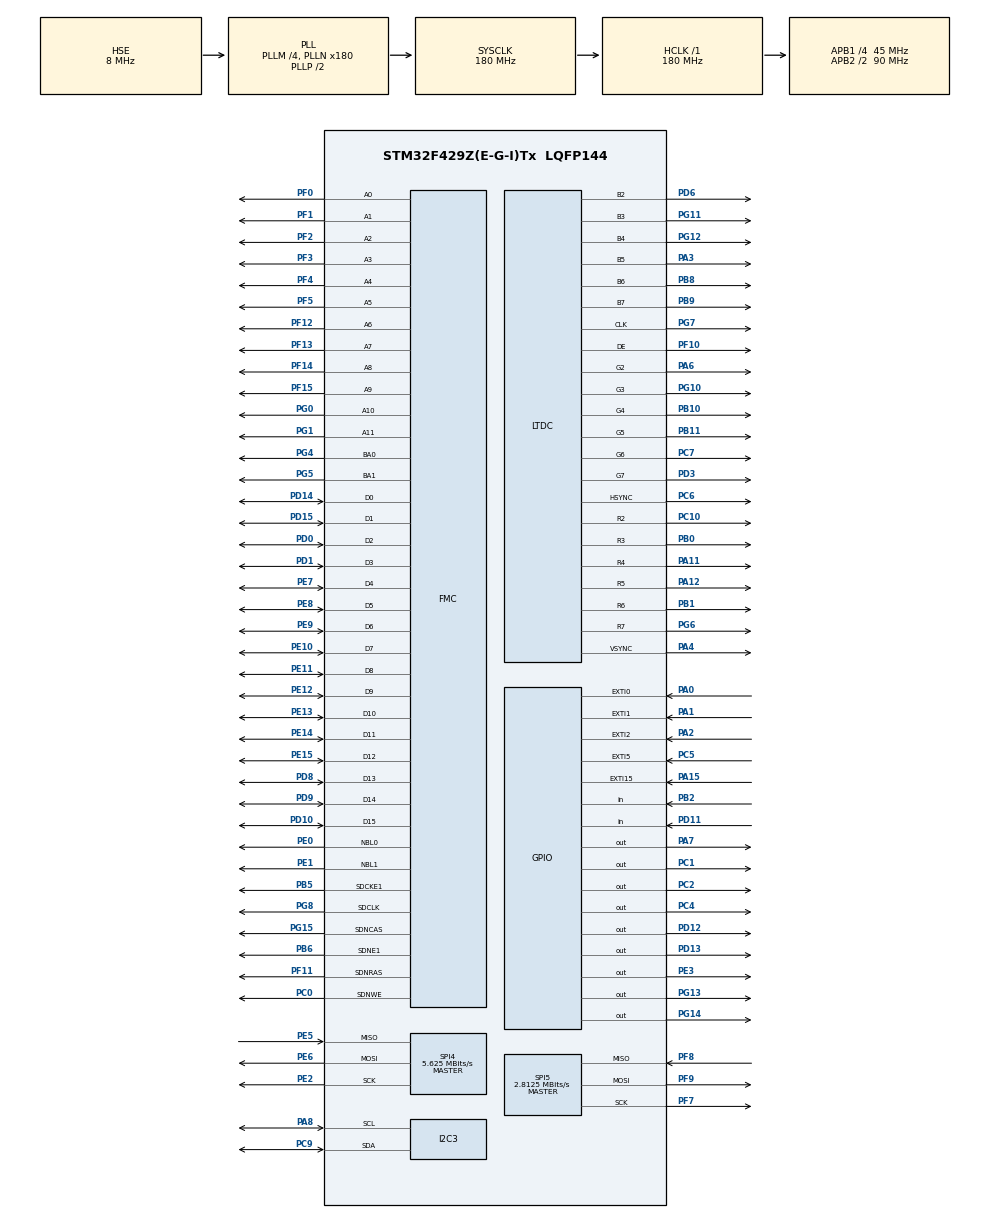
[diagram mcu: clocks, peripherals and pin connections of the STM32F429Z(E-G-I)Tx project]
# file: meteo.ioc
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DMA2D.InputColorModeForeground=DMA2D_INPUT_RGB888
DMA2D.Mode=DMA2D_M2M_PFC
FMC.CASLatency1=FMC_SDRAM_CAS_LATENCY_3
FMC.ExitSelfRefreshDelay1=7
FMC.LoadToActiveDelay1=2
FMC.RCDDelay1=2
FMC.RPDelay1=2
FMC.RPDelay2=2
FMC.ReadPipeDelay1=FMC_SDRAM_RPIPE_DELAY_1
FMC.ReadPipeDelay2=FMC_SDRAM_RPIPE_DELAY_1
FMC.RowCycleDelay1=7
FMC.RowCycleDelay2=7
FMC.SelfRefreshTime1=4
FMC.WriteRecoveryTime1=3
LTDC.ActiveH=320
LTDC.ActiveW=240
LTDC.Alpha0_L0=0
LTDC.Alpha_L0=255
LTDC.BlendingFactor1_L0=LTDC_BLENDING_FACTOR1_PAxCA
LTDC.BlendingFactor2_L0=LTDC_BLENDING_FACTOR2_PAxCA
LTDC.HBP=20
LTDC.HFP=10
LTDC.HSync=10
LTDC.ImageHeight_L0=320
LTDC.ImageWidth_L0=240
LTDC.Layers=0
LTDC.VFP=4
LTDC.VSync=2
LTDC.WindowX1_L0=240
LTDC.WindowY1_L0=320
Mcu.Family=STM32F4
Mcu.Name=STM32F429Z(E-G-I)Tx
Mcu.Package=LQFP144
NVIC.FMC_IRQn=true\:0\:0\:false\:false\:true
NVIC.PriorityGroup=NVIC_PRIORITYGROUP_0
PA0/WKUP.GPIO_ModeDefaultEXTI=GPIO_MODE_IT_RISING
PA0/WKUP.GPIO_PuPd=GPIO_NOPULL
PA0/WKUP.Signal=GPXTI0
PA1.GPIO_ModeDefaultEXTI=GPIO_MODE_IT_RISING
PA1.GPIO_PuPd=GPIO_NOPULL
PA1.Signal=GPXTI1
PA11.GPIO_Mode=GPIO_MODE_AF_PP
PA11.GPIO_PuPd=GPIO_NOPULL
PA11.GPIO_Speed=GPIO_SPEED_FREQ_HIGH
PA11.Mode=RGB666
PA11.Signal=LTDC_R4
PA12.GPIO_Mode=GPIO_MODE_AF_PP
PA12.GPIO_PuPd=GPIO_NOPULL
PA12.GPIO_Speed=GPIO_SPEED_FREQ_HIGH
PA12.Mode=RGB666
PA12.Signal=LTDC_R5
PA13.Mode=Trace_Asynchronous_SW
PA13.Signal=SYS_JTMS-SWDIO
PA14.Mode=Trace_Asynchronous_SW
PA14.Signal=SYS_JTCK-SWCLK
PA15.GPIO_ModeDefaultEXTI=GPIO_MODE_IT_RISING
PA15.GPIO_PuPd=GPIO_NOPULL
PA15.Signal=GPXTI15
PA2.GPIO_ModeDefaultEXTI=GPIO_MODE_IT_RISING
PA2.GPIO_PuPd=GPIO_NOPULL
PA2.Signal=GPXTI2
PA3.GPIO_Mode=GPIO_MODE_AF_PP
PA3.GPIO_PuPd=GPIO_NOPULL
PA3.GPIO_Speed=GPIO_SPEED_FREQ_HIGH
PA3.Mode=RGB666
PA3.Signal=LTDC_B5
PA4.GPIO_Mode=GPIO_MODE_AF_PP
PA4.GPIO_PuPd=GPIO_NOPULL
PA4.GPIO_Speed=GPIO_SPEED_FREQ_HIGH
PA4.Mode=RGB666
PA4.Signal=LTDC_VSYNC
PA6.GPIO_Mode=GPIO_MODE_AF_PP
PA6.GPIO_PuPd=GPIO_NOPULL
PA6.GPIO_Speed=GPIO_SPEED_FREQ_HIGH
PA6.Mode=RGB666
PA6.Signal=LTDC_G2
PA7.GPIO_Mode=GPIO_MODE_OUTPUT_PP
PA7.GPIO_ModeDefaultOutputPP=GPIO_MODE_OUTPUT_PP
PA7.GPIO_PuPd=GPIO_NOPULL
PA7.GPIO_Speed=GPIO_SPEED_FREQ_LOW
PA7.PinState=GPIO_PIN_RESET
PA7.Signal=GPIO_Output
PA8.GPIO_Mode=GPIO_MODE_AF_OD
PA8.GPIO_PuPd=GPIO_NOPULL
PA8.GPIO_PuPdOD=GPIO_PULLUP
PA8.GPIO_Speed=GPIO_SPEED_FREQ_VERY_HIGH
PA8.Mode=I2C
PA8.Signal=I2C3_SCL
PB0.GPIO_Mode=GPIO_MODE_AF_PP
PB0.GPIO_PuPd=GPIO_NOPULL
PB0.GPIO_Speed=GPIO_SPEED_FREQ_HIGH
PB0.Mode=RGB666
PB0.Signal=LTDC_R3
PB1.GPIO_Mode=GPIO_MODE_AF_PP
PB1.GPIO_PuPd=GPIO_NOPULL
PB1.GPIO_Speed=GPIO_SPEED_FREQ_HIGH
PB1.Mode=RGB666
PB1.Signal=LTDC_R6
PB10.GPIO_Mode=GPIO_MODE_AF_PP
PB10.GPIO_PuPd=GPIO_NOPULL
PB10.GPIO_Speed=GPIO_SPEED_FREQ_HIGH
PB10.Mode=RGB666
PB10.Signal=LTDC_G4
PB11.GPIO_Mode=GPIO_MODE_AF_PP
PB11.GPIO_PuPd=GPIO_NOPULL
PB11.GPIO_Speed=GPIO_SPEED_FREQ_HIGH
PB11.Mode=RGB666
PB11.Signal=LTDC_G5
PB12.GPIO_Mode=GPIO_MODE_AF_PP
PB12.GPIO_PuPd=GPIO_NOPULL
PB12.GPIO_Speed=GPIO_SPEED_FREQ_VERY_HIGH
PB12.Signal=USB_OTG_HS_ID
PB13.GPIO_Mode=GPIO_MODE_INPUT
PB13.GPIO_PuPd=GPIO_NOPULL
PB13.Signal=USB_OTG_HS_VBUS
PB14.GPIO_Mode=GPIO_MODE_AF_PP
PB14.GPIO_PuPd=GPIO_NOPULL
PB14.GPIO_Speed=GPIO_SPEED_FREQ_VERY_HIGH
PB14.Signal=USB_OTG_HS_DM
PB15.GPIO_Mode=GPIO_MODE_AF_PP
PB15.GPIO_PuPd=GPIO_NOPULL
PB15.GPIO_Speed=GPIO_SPEED_FREQ_VERY_HIGH
PB15.Signal=USB_OTG_HS_DP
PB2/BOOT1.GPIO_Mode=GPIO_MODE_INPUT
PB2/BOOT1.GPIO_PuPd=GPIO_NOPULL
PB2/BOOT1.Signal=GPIO_Input
PB3.Mode=Trace_Asynchronous_SW
PB3.Signal=SYS_JTDO-SWO
PB5.GPIO_Mode=GPIO_MODE_AF_PP
PB5.GPIO_PuPd=GPIO_NOPULL
PB5.GPIO_Speed=GPIO_SPEED_FREQ_VERY_HIGH
PB5.GPIO_Speed_High_Default=GPIO_SPEED_FREQ_VERY_HIGH
PB5.Mode=SdramChipSelect2_1
PB5.Signal=FMC_SDCKE1
PB6.GPIO_Mode=GPIO_MODE_AF_PP
PB6.GPIO_PuPd=GPIO_NOPULL
PB6.GPIO_Speed=GPIO_SPEED_FREQ_VERY_HIGH
PB6.GPIO_Speed_High_Default=GPIO_SPEED_FREQ_VERY_HIGH
PB6.Mode=SdramChipSelect2_1
PB6.Signal=FMC_SDNE1
PB8.GPIO_Mode=GPIO_MODE_AF_PP
PB8.GPIO_PuPd=GPIO_NOPULL
PB8.GPIO_Speed=GPIO_SPEED_FREQ_HIGH
PB8.Mode=RGB666
PB8.Signal=LTDC_B6
PB9.GPIO_Mode=GPIO_MODE_AF_PP
PB9.GPIO_PuPd=GPIO_NOPULL
PB9.GPIO_Speed=GPIO_SPEED_FREQ_HIGH
PB9.Mode=RGB666
PB9.Signal=LTDC_B7
PC0.GPIO_Mode=GPIO_MODE_AF_PP
PC0.GPIO_PuPd=GPIO_NOPULL
PC0.GPIO_Speed=GPIO_SPEED_FREQ_VERY_HIGH
PC0.GPIO_Speed_High_Default=GPIO_SPEED_FREQ_VERY_HIGH
PC0.Signal=FMC_SDNWE
PC1.GPIO_Mode=GPIO_MODE_OUTPUT_PP
PC1.GPIO_ModeDefaultOutputPP=GPIO_MODE_OUTPUT_PP
PC1.GPIO_PuPd=GPIO_NOPULL
PC1.GPIO_Speed=GPIO_SPEED_FREQ_LOW
PC1.PinState=GPIO_PIN_RESET
PC1.Signal=GPIO_Output
PC10.GPIO_Mode=GPIO_MODE_AF_PP
PC10.GPIO_PuPd=GPIO_NOPULL
PC10.GPIO_Speed=GPIO_SPEED_FREQ_HIGH
PC10.Mode=RGB666
PC10.Signal=LTDC_R2
PC14/OSC32_IN.Signal=RCC_OSC32_IN
PC15/OSC32_OUT.Signal=RCC_OSC32_OUT
PC2.GPIO_Mode=GPIO_MODE_OUTPUT_PP
PC2.GPIO_ModeDefaultOutputPP=GPIO_MODE_OUTPUT_PP
PC2.GPIO_PuPd=GPIO_NOPULL
PC2.GPIO_Speed=GPIO_SPEED_FREQ_LOW
PC2.PinState=GPIO_PIN_RESET
PC2.Signal=GPIO_Output
PC4.GPIO_Mode=GPIO_MODE_OUTPUT_PP
PC4.GPIO_ModeDefaultOutputPP=GPIO_MODE_OUTPUT_PP
PC4.GPIO_PuPd=GPIO_NOPULL
PC4.GPIO_Speed=GPIO_SPEED_FREQ_LOW
PC4.PinState=GPIO_PIN_RESET
PC4.Signal=GPIO_Output
PC5.GPIO_ModeDefaultEXTI=GPIO_MODE_IT_RISING
PC5.GPIO_PuPd=GPIO_NOPULL
PC5.Signal=GPXTI5
PC6.GPIO_Mode=GPIO_MODE_AF_PP
PC6.GPIO_PuPd=GPIO_NOPULL
PC6.GPIO_Speed=GPIO_SPEED_FREQ_HIGH
PC6.Mode=RGB666
PC6.Signal=LTDC_HSYNC
PC7.GPIO_Mode=GPIO_MODE_AF_PP
PC7.GPIO_PuPd=GPIO_NOPULL
PC7.GPIO_Speed=GPIO_SPEED_FREQ_HIGH
PC7.Mode=RGB666
PC7.Signal=LTDC_G6
PC9.GPIO_Mode=GPIO_MODE_AF_OD
PC9.GPIO_PuPd=GPIO_NOPULL
PC9.GPIO_PuPdOD=GPIO_PULLUP
PC9.GPIO_Speed=GPIO_SPEED_FREQ_VERY_HIGH
PC9.Mode=I2C
PC9.Signal=I2C3_SDA
PD0.GPIO_Mode=GPIO_MODE_AF_PP
PD0.GPIO_PuPd=GPIO_NOPULL
PD0.GPIO_Speed=GPIO_SPEED_FREQ_VERY_HIGH
PD0.GPIO_Speed_High_Default=GPIO_SPEED_FREQ_VERY_HIGH
PD0.Signal=FMC_D2_DA2
PD1.GPIO_Mode=GPIO_MODE_AF_PP
PD1.GPIO_PuPd=GPIO_NOPULL
PD1.GPIO_Speed=GPIO_SPEED_FREQ_VERY_HIGH
PD1.GPIO_Speed_High_Default=GPIO_SPEED_FREQ_VERY_HIGH
PD1.Signal=FMC_D3_DA3
PD10.GPIO_Mode=GPIO_MODE_AF_PP
PD10.GPIO_PuPd=GPIO_NOPULL
PD10.GPIO_Speed=GPIO_SPEED_FREQ_VERY_HIGH
PD10.GPIO_Speed_High_Default=GPIO_SPEED_FREQ_VERY_HIGH
PD10.Signal=FMC_D15_DA15
PD11.GPIO_Mode=GPIO_MODE_INPUT
PD11.GPIO_PuPd=GPIO_NOPULL
PD11.Signal=GPIO_Input
PD12.GPIO_Mode=GPIO_MODE_OUTPUT_PP
PD12.GPIO_ModeDefaultOutputPP=GPIO_MODE_OUTPUT_PP
PD12.GPIO_PuPd=GPIO_NOPULL
PD12.GPIO_Speed=GPIO_SPEED_FREQ_LOW
PD12.PinState=GPIO_PIN_RESET
PD12.Signal=GPIO_Output
PD13.GPIO_Mode=GPIO_MODE_OUTPUT_PP
PD13.GPIO_ModeDefaultOutputPP=GPIO_MODE_OUTPUT_PP
PD13.GPIO_PuPd=GPIO_NOPULL
PD13.GPIO_Speed=GPIO_SPEED_FREQ_LOW
PD13.PinState=GPIO_PIN_RESET
PD13.Signal=GPIO_Output
PD14.GPIO_Mode=GPIO_MODE_AF_PP
PD14.GPIO_PuPd=GPIO_NOPULL
PD14.GPIO_Speed=GPIO_SPEED_FREQ_VERY_HIGH
PD14.GPIO_Speed_High_Default=GPIO_SPEED_FREQ_VERY_HIGH
PD14.Signal=FMC_D0_DA0
PD15.GPIO_Mode=GPIO_MODE_AF_PP
PD15.GPIO_PuPd=GPIO_NOPULL
PD15.GPIO_Speed=GPIO_SPEED_FREQ_VERY_HIGH
PD15.GPIO_Speed_High_Default=GPIO_SPEED_FREQ_VERY_HIGH
PD15.Signal=FMC_D1_DA1
PD3.GPIO_Mode=GPIO_MODE_AF_PP
PD3.GPIO_PuPd=GPIO_NOPULL
PD3.GPIO_Speed=GPIO_SPEED_FREQ_HIGH
PD3.Mode=RGB666
PD3.Signal=LTDC_G7
PD6.GPIO_Mode=GPIO_MODE_AF_PP
PD6.GPIO_PuPd=GPIO_NOPULL
PD6.GPIO_Speed=GPIO_SPEED_FREQ_HIGH
PD6.Mode=RGB666
PD6.Signal=LTDC_B2
PD8.GPIO_Mode=GPIO_MODE_AF_PP
PD8.GPIO_PuPd=GPIO_NOPULL
PD8.GPIO_Speed=GPIO_SPEED_FREQ_VERY_HIGH
PD8.GPIO_Speed_High_Default=GPIO_SPEED_FREQ_VERY_HIGH
PD8.Signal=FMC_D13_DA13
PD9.GPIO_Mode=GPIO_MODE_AF_PP
PD9.GPIO_PuPd=GPIO_NOPULL
PD9.GPIO_Speed=GPIO_SPEED_FREQ_VERY_HIGH
PD9.GPIO_Speed_High_Default=GPIO_SPEED_FREQ_VERY_HIGH
PD9.Signal=FMC_D14_DA14
PE0.GPIO_Mode=GPIO_MODE_AF_PP
PE0.GPIO_PuPd=GPIO_NOPULL
PE0.GPIO_Speed=GPIO_SPEED_FREQ_VERY_HIGH
PE0.GPIO_Speed_High_Default=GPIO_SPEED_FREQ_VERY_HIGH
PE0.Signal=FMC_NBL0
PE1.GPIO_Mode=GPIO_MODE_AF_PP
PE1.GPIO_PuPd=GPIO_NOPULL
PE1.GPIO_Speed=GPIO_SPEED_FREQ_VERY_HIGH
PE1.GPIO_Speed_High_Default=GPIO_SPEED_FREQ_VERY_HIGH
PE1.Signal=FMC_NBL1
PE10.GPIO_Mode=GPIO_MODE_AF_PP
PE10.GPIO_PuPd=GPIO_NOPULL
PE10.GPIO_Speed=GPIO_SPEED_FREQ_VERY_HIGH
PE10.GPIO_Speed_High_Default=GPIO_SPEED_FREQ_VERY_HIGH
PE10.Signal=FMC_D7_DA7
PE11.GPIO_Mode=GPIO_MODE_AF_PP
PE11.GPIO_PuPd=GPIO_NOPULL
PE11.GPIO_Speed=GPIO_SPEED_FREQ_VERY_HIGH
PE11.GPIO_Speed_High_Default=GPIO_SPEED_FREQ_VERY_HIGH
PE11.Signal=FMC_D8_DA8
PE12.GPIO_Mode=GPIO_MODE_AF_PP
PE12.GPIO_PuPd=GPIO_NOPULL
PE12.GPIO_Speed=GPIO_SPEED_FREQ_VERY_HIGH
PE12.GPIO_Speed_High_Default=GPIO_SPEED_FREQ_VERY_HIGH
PE12.Signal=FMC_D9_DA9
PE13.GPIO_Mode=GPIO_MODE_AF_PP
PE13.GPIO_PuPd=GPIO_NOPULL
PE13.GPIO_Speed=GPIO_SPEED_FREQ_VERY_HIGH
PE13.GPIO_Speed_High_Default=GPIO_SPEED_FREQ_VERY_HIGH
PE13.Signal=FMC_D10_DA10
PE14.GPIO_Mode=GPIO_MODE_AF_PP
PE14.GPIO_PuPd=GPIO_NOPULL
PE14.GPIO_Speed=GPIO_SPEED_FREQ_VERY_HIGH
PE14.GPIO_Speed_High_Default=GPIO_SPEED_FREQ_VERY_HIGH
PE14.Signal=FMC_D11_DA11
PE15.GPIO_Mode=GPIO_MODE_AF_PP
PE15.GPIO_PuPd=GPIO_NOPULL
PE15.GPIO_Speed=GPIO_SPEED_FREQ_VERY_HIGH
PE15.GPIO_Speed_High_Default=GPIO_SPEED_FREQ_VERY_HIGH
PE15.Signal=FMC_D12_DA12
PE2.Mode=Full_Duplex_Master
PE2.Signal=SPI4_SCK
PE3.GPIO_ModeDefaultOutputPP=GPIO_MODE_OUTPUT_PP
PE3.GPIO_PuPd=GPIO_NOPULL
PE3.GPIO_Speed=GPIO_SPEED_FREQ_LOW
PE3.PinState=GPIO_PIN_RESET
PE3.Signal=GPIO_Output
PE5.Mode=Full_Duplex_Master
PE5.Signal=SPI4_MISO
PE6.Mode=Full_Duplex_Master
PE6.Signal=SPI4_MOSI
PE7.GPIO_Mode=GPIO_MODE_AF_PP
PE7.GPIO_PuPd=GPIO_NOPULL
PE7.GPIO_Speed=GPIO_SPEED_FREQ_VERY_HIGH
PE7.GPIO_Speed_High_Default=GPIO_SPEED_FREQ_VERY_HIGH
PE7.Signal=FMC_D4_DA4
PE8.GPIO_Mode=GPIO_MODE_AF_PP
PE8.GPIO_PuPd=GPIO_NOPULL
PE8.GPIO_Speed=GPIO_SPEED_FREQ_VERY_HIGH
PE8.GPIO_Speed_High_Default=GPIO_SPEED_FREQ_VERY_HIGH
PE8.Signal=FMC_D5_DA5
PE9.GPIO_Mode=GPIO_MODE_AF_PP
PE9.GPIO_PuPd=GPIO_NOPULL
PE9.GPIO_Speed=GPIO_SPEED_FREQ_VERY_HIGH
PE9.GPIO_Speed_High_Default=GPIO_SPEED_FREQ_VERY_HIGH
PE9.Signal=FMC_D6_DA6
PF0.GPIO_Mode=GPIO_MODE_AF_PP
PF0.GPIO_PuPd=GPIO_NOPULL
PF0.GPIO_Speed=GPIO_SPEED_FREQ_VERY_HIGH
PF0.GPIO_Speed_High_Default=GPIO_SPEED_FREQ_VERY_HIGH
PF0.Signal=FMC_A0
PF1.GPIO_Mode=GPIO_MODE_AF_PP
PF1.GPIO_PuPd=GPIO_NOPULL
PF1.GPIO_Speed=GPIO_SPEED_FREQ_VERY_HIGH
PF1.GPIO_Speed_High_Default=GPIO_SPEED_FREQ_VERY_HIGH
PF1.Signal=FMC_A1
PF10.GPIO_Mode=GPIO_MODE_AF_PP
PF10.GPIO_PuPd=GPIO_NOPULL
PF10.GPIO_Speed=GPIO_SPEED_FREQ_HIGH
PF10.Mode=RGB666
PF10.Signal=LTDC_DE
PF11.GPIO_Mode=GPIO_MODE_AF_PP
PF11.GPIO_PuPd=GPIO_NOPULL
PF11.GPIO_Speed=GPIO_SPEED_FREQ_VERY_HIGH
PF11.GPIO_Speed_High_Default=GPIO_SPEED_FREQ_VERY_HIGH
PF11.Signal=FMC_SDNRAS
PF12.GPIO_Mode=GPIO_MODE_AF_PP
PF12.GPIO_PuPd=GPIO_NOPULL
PF12.GPIO_Speed=GPIO_SPEED_FREQ_VERY_HIGH
PF12.GPIO_Speed_High_Default=GPIO_SPEED_FREQ_VERY_HIGH
PF12.Signal=FMC_A6
PF13.GPIO_Mode=GPIO_MODE_AF_PP
PF13.GPIO_PuPd=GPIO_NOPULL
PF13.GPIO_Speed=GPIO_SPEED_FREQ_VERY_HIGH
PF13.GPIO_Speed_High_Default=GPIO_SPEED_FREQ_VERY_HIGH
PF13.Signal=FMC_A7
PF14.GPIO_Mode=GPIO_MODE_AF_PP
PF14.GPIO_PuPd=GPIO_NOPULL
PF14.GPIO_Speed=GPIO_SPEED_FREQ_VERY_HIGH
PF14.GPIO_Speed_High_Default=GPIO_SPEED_FREQ_VERY_HIGH
PF14.Signal=FMC_A8
PF15.GPIO_Mode=GPIO_MODE_AF_PP
PF15.GPIO_PuPd=GPIO_NOPULL
PF15.GPIO_Speed=GPIO_SPEED_FREQ_VERY_HIGH
PF15.GPIO_Speed_High_Default=GPIO_SPEED_FREQ_VERY_HIGH
PF15.Signal=FMC_A9
PF2.GPIO_Mode=GPIO_MODE_AF_PP
PF2.GPIO_PuPd=GPIO_NOPULL
PF2.GPIO_Speed=GPIO_SPEED_FREQ_VERY_HIGH
PF2.GPIO_Speed_High_Default=GPIO_SPEED_FREQ_VERY_HIGH
PF2.Signal=FMC_A2
PF3.GPIO_Mode=GPIO_MODE_AF_PP
PF3.GPIO_PuPd=GPIO_NOPULL
PF3.GPIO_Speed=GPIO_SPEED_FREQ_VERY_HIGH
PF3.GPIO_Speed_High_Default=GPIO_SPEED_FREQ_VERY_HIGH
PF3.Signal=FMC_A3
PF4.GPIO_Mode=GPIO_MODE_AF_PP
PF4.GPIO_PuPd=GPIO_NOPULL
PF4.GPIO_Speed=GPIO_SPEED_FREQ_VERY_HIGH
PF4.GPIO_Speed_High_Default=GPIO_SPEED_FREQ_VERY_HIGH
PF4.Signal=FMC_A4
PF5.GPIO_Mode=GPIO_MODE_AF_PP
PF5.GPIO_PuPd=GPIO_NOPULL
PF5.GPIO_Speed=GPIO_SPEED_FREQ_VERY_HIGH
PF5.GPIO_Speed_High_Default=GPIO_SPEED_FREQ_VERY_HIGH
PF5.Signal=FMC_A5
PF7.GPIO_Mode=GPIO_MODE_AF_PP
PF7.GPIO_PuPd=GPIO_NOPULL
PF7.GPIO_Speed=GPIO_SPEED_FREQ_VERY_HIGH
PF7.Mode=Full_Duplex_Master
PF7.Signal=SPI5_SCK
PF8.GPIO_Mode=GPIO_MODE_AF_PP
PF8.GPIO_PuPd=GPIO_NOPULL
PF8.GPIO_Speed=GPIO_SPEED_FREQ_VERY_HIGH
PF8.Mode=Full_Duplex_Master
PF8.Signal=SPI5_MISO
PF9.GPIO_Mode=GPIO_MODE_AF_PP
PF9.GPIO_PuPd=GPIO_NOPULL
PF9.GPIO_Speed=GPIO_SPEED_FREQ_VERY_HIGH
PF9.Mode=Full_Duplex_Master
PF9.Signal=SPI5_MOSI
PG0.GPIO_Mode=GPIO_MODE_AF_PP
PG0.GPIO_PuPd=GPIO_NOPULL
PG0.GPIO_Speed=GPIO_SPEED_FREQ_VERY_HIGH
PG0.GPIO_Speed_High_Default=GPIO_SPEED_FREQ_VERY_HIGH
PG0.Signal=FMC_A10
PG1.GPIO_Mode=GPIO_MODE_AF_PP
PG1.GPIO_PuPd=GPIO_NOPULL
PG1.GPIO_Speed=GPIO_SPEED_FREQ_VERY_HIGH
PG1.GPIO_Speed_High_Default=GPIO_SPEED_FREQ_VERY_HIGH
PG1.Signal=FMC_A11
PG10.GPIO_Mode=GPIO_MODE_AF_PP
PG10.GPIO_PuPd=GPIO_NOPULL
PG10.GPIO_Speed=GPIO_SPEED_FREQ_HIGH
PG10.Mode=RGB666
PG10.Signal=LTDC_G3
PG11.GPIO_Mode=GPIO_MODE_AF_PP
PG11.GPIO_PuPd=GPIO_NOPULL
PG11.GPIO_Speed=GPIO_SPEED_FREQ_HIGH
PG11.Mode=RGB666
PG11.Signal=LTDC_B3
PG12.GPIO_Mode=GPIO_MODE_AF_PP
PG12.GPIO_PuPd=GPIO_NOPULL
PG12.GPIO_Speed=GPIO_SPEED_FREQ_HIGH
PG12.Mode=RGB666
PG12.Signal=LTDC_B4
PG13.GPIO_Mode=GPIO_MODE_OUTPUT_PP
PG13.GPIO_ModeDefaultOutputPP=GPIO_MODE_OUTPUT_PP
PG13.GPIO_PuPd=GPIO_NOPULL
PG13.GPIO_Speed=GPIO_SPEED_FREQ_LOW
PG13.PinState=GPIO_PIN_RESET
PG13.Signal=GPIO_Output
PG14.GPIO_Mode=GPIO_MODE_OUTPUT_PP
PG14.GPIO_ModeDefaultOutputPP=GPIO_MODE_OUTPUT_PP
PG14.GPIO_PuPd=GPIO_NOPULL
PG14.GPIO_Speed=GPIO_SPEED_FREQ_LOW
PG14.PinState=GPIO_PIN_RESET
PG14.Signal=GPIO_Output
PG15.GPIO_Mode=GPIO_MODE_AF_PP
PG15.GPIO_PuPd=GPIO_NOPULL
PG15.GPIO_Speed=GPIO_SPEED_FREQ_VERY_HIGH
PG15.GPIO_Speed_High_Default=GPIO_SPEED_FREQ_VERY_HIGH
PG15.Signal=FMC_SDNCAS
PG4.GPIO_Mode=GPIO_MODE_AF_PP
PG4.GPIO_PuPd=GPIO_NOPULL
PG4.GPIO_Speed=GPIO_SPEED_FREQ_VERY_HIGH
PG4.GPIO_Speed_High_Default=GPIO_SPEED_FREQ_VERY_HIGH
PG4.Signal=FMC_A14_BA0
PG5.GPIO_Mode=GPIO_MODE_AF_PP
PG5.GPIO_PuPd=GPIO_NOPULL
PG5.GPIO_Speed=GPIO_SPEED_FREQ_VERY_HIGH
PG5.GPIO_Speed_High_Default=GPIO_SPEED_FREQ_VERY_HIGH
PG5.Signal=FMC_A15_BA1
PG6.GPIO_Mode=GPIO_MODE_AF_PP
PG6.GPIO_PuPd=GPIO_NOPULL
PG6.GPIO_Speed=GPIO_SPEED_FREQ_HIGH
PG6.Mode=RGB666
PG6.Signal=LTDC_R7
PG7.GPIO_Mode=GPIO_MODE_AF_PP
PG7.GPIO_PuPd=GPIO_NOPULL
PG7.GPIO_Speed=GPIO_SPEED_FREQ_HIGH
PG7.Mode=RGB666
PG7.Signal=LTDC_CLK
PG8.GPIO_Mode=GPIO_MODE_AF_PP
PG8.GPIO_PuPd=GPIO_NOPULL
PG8.GPIO_Speed=GPIO_SPEED_FREQ_VERY_HIGH
PG8.GPIO_Speed_High_Default=GPIO_SPEED_FREQ_VERY_HIGH
PG8.Signal=FMC_SDCLK
PH0/OSC_IN.Mode=HSE-External-Oscillator
PH0/OSC_IN.Signal=RCC_OSC_IN
PH1/OSC_OUT.Mode=HSE-External-Oscillator
PH1/OSC_OUT.Signal=RCC_OSC_OUT
ProjectManager.HeapSize=0x400
ProjectManager.StackSize=0x400
ProjectManager.TargetToolchain=SW4STM32
RCC.48MHZClocksFreq_Value=51428571.428571425
RCC.AHBFreq_Value=180000000
RCC.APB1CLKDivider=RCC_HCLK_DIV4
RCC.APB1Freq_Value=45000000
RCC.APB1TimFreq_Value=90000000
RCC.APB2CLKDivider=RCC_HCLK_DIV2
RCC.APB2Freq_Value=90000000
RCC.APB2TimFreq_Value=180000000
RCC.CortexFreq_Value=180000000
RCC.HCLKFreq_Value=180000000
RCC.HSE_VALUE=8000000
RCC.HSI_VALUE=16000000
RCC.LSE_VALUE=32768
RCC.PLLM=4
RCC.PLLN=180
RCC.PLLQ=7
RCC.PLLSAIDivR=RCC_PLLSAIDIVR_4
RCC.PLLSAIN=60
RCC.PLLSAIR=5
RCC.PLLSourceVirtual=RCC_PLLSOURCE_HSE
RCC.SYSCLKFreq_VALUE=180000000
RCC.SYSCLKSource=RCC_SYSCLKSOURCE_PLLCLK
RCC.VCOOutputFreq_Value=360000000
SH.FMC_A0.0=FMC_A0,12b-sda1
SH.FMC_A1.0=FMC_A1,12b-sda1
SH.FMC_A10.0=FMC_A10,12b-sda1
SH.FMC_A11.0=FMC_A11,12b-sda1
SH.FMC_A14_BA0.0=FMC_BA0,FourSdramBanks1
SH.FMC_A15_BA1.0=FMC_BA1,FourSdramBanks1
SH.FMC_A2.0=FMC_A2,12b-sda1
SH.FMC_A3.0=FMC_A3,12b-sda1
SH.FMC_A4.0=FMC_A4,12b-sda1
SH.FMC_A5.0=FMC_A5,12b-sda1
SH.FMC_A6.0=FMC_A6,12b-sda1
SH.FMC_A7.0=FMC_A7,12b-sda1
SH.FMC_A8.0=FMC_A8,12b-sda1
SH.FMC_A9.0=FMC_A9,12b-sda1
SH.FMC_D0_DA0.0=FMC_D0,sd-16b-d1
SH.FMC_D10_DA10.0=FMC_D10,sd-16b-d1
SH.FMC_D11_DA11.0=FMC_D11,sd-16b-d1
SH.FMC_D12_DA12.0=FMC_D12,sd-16b-d1
SH.FMC_D13_DA13.0=FMC_D13,sd-16b-d1
SH.FMC_D14_DA14.0=FMC_D14,sd-16b-d1
SH.FMC_D15_DA15.0=FMC_D15,sd-16b-d1
SH.FMC_D1_DA1.0=FMC_D1,sd-16b-d1
SH.FMC_D2_DA2.0=FMC_D2,sd-16b-d1
SH.FMC_D3_DA3.0=FMC_D3,sd-16b-d1
SH.FMC_D4_DA4.0=FMC_D4,sd-16b-d1
SH.FMC_D5_DA5.0=FMC_D5,sd-16b-d1
SH.FMC_D6_DA6.0=FMC_D6,sd-16b-d1
SH.FMC_D7_DA7.0=FMC_D7,sd-16b-d1
SH.FMC_D8_DA8.0=FMC_D8,sd-16b-d1
SH.FMC_D9_DA9.0=FMC_D9,sd-16b-d1
SH.FMC_NBL0.0=FMC_NBL0,Sd2ByteEnable1
SH.FMC_NBL1.0=FMC_NBL1,Sd2ByteEnable1
SH.FMC_SDCLK.0=FMC_SDCLK,12b-sda1
SH.FMC_SDNCAS.0=FMC_SDNCAS,12b-sda1
SH.FMC_SDNRAS.0=FMC_SDNRAS,12b-sda1
SH.FMC_SDNWE.0=FMC_SDNWE,12b-sda1
SPI4.BaudRatePrescaler=SPI_BAUDRATEPRESCALER_16
SPI4.CalculateBaudRate=5.625 MBits/s
SPI4.Direction=SPI_DIRECTION_2LINES
SPI4.Mode=SPI_MODE_MASTER
SPI4.VirtualType=VM_MASTER
SPI5.BaudRatePrescaler=SPI_BAUDRATEPRESCALER_32
SPI5.CalculateBaudRate=2.8125 MBits/s
SPI5.Direction=SPI_DIRECTION_2LINES
SPI5.Mode=SPI_MODE_MASTER
SPI5.VirtualType=VM_MASTER
VP_DMA2D_VS_DMA2D.Mode=DMA2D_Activate
board=STM32F429I-DISCO

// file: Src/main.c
/**
  ******************************************************************************
  * File Name          : main.c
  * Description        : Main program body
  ******************************************************************************
  ** This notice applies to any and all portions of this file
  * that are not between comment pairs USER CODE BEGIN and
  * USER CODE END. Other portions of this file, whether
  * inserted by the user or by software development tools
  * are owned by their respective copyright owners.
  *
  * COPYRIGHT(c) 2017 STMicroelectronics
  *
  * Redistribution and use in source and binary forms, with or without modification,
  * are permitted provided that the following conditions are met:
  *   1. Redistributions of source code must retain the above copyright notice,
  *      this list of conditions and the following disclaimer.
  *   2. Redistributions in binary form must reproduce the above copyright notice,
  *      this list of conditions and the following disclaimer in the documentation
  *      and/or other materials provided with the distribution.
  *   3. Neither the name of STMicroelectronics nor the names of its contributors
  *      may be used to endorse or promote products derived from this software
  *      without specific prior written permission.
  *
  * THIS SOFTWARE IS PROVIDED BY THE COPYRIGHT HOLDERS AND CONTRIBUTORS "AS IS"
  * AND ANY EXPRESS OR IMPLIED WARRANTIES, INCLUDING, BUT NOT LIMITED TO, THE
  * IMPLIED WARRANTIES OF MERCHANTABILITY AND FITNESS FOR A PARTICULAR PURPOSE ARE
  * DISCLAIMED. IN NO EVENT SHALL THE COPYRIGHT HOLDER OR CONTRIBUTORS BE LIABLE
  * FOR ANY DIRECT, INDIRECT, INCIDENTAL, SPECIAL, EXEMPLARY, OR CONSEQUENTIAL
  * DAMAGES (INCLUDING, BUT NOT LIMITED TO, PROCUREMENT OF SUBSTITUTE GOODS OR
  * SERVICES; LOSS OF USE, DATA, OR PROFITS; OR BUSINESS INTERRUPTION) HOWEVER
  * CAUSED AND ON ANY THEORY OF LIABILITY, WHETHER IN CONTRACT, STRICT LIABILITY,
  * OR TORT (INCLUDING NEGLIGENCE OR OTHERWISE) ARISING IN ANY WAY OUT OF THE USE
  * OF THIS SOFTWARE, EVEN IF ADVISED OF THE POSSIBILITY OF SUCH DAMAGE.
  *
  ******************************************************************************
  */
#include "main.h"
#include "stm32f4xx_hal.h"
#include "dma2d.h"
#include "i2c.h"
#include "ltdc.h"
#include "spi.h"
#include "gpio.h"
#include "fmc.h"

/* USER CODE BEGIN Includes */
#include "stm32f429i_discovery.h"
#include "stm32f429i_discovery_lcd.h"
#include "lcd_log.h"
#include "bme280.h"
/* USER CODE END Includes */

/* USER CODE BEGIN PV */
/* Private variables ---------------------------------------------------------*/
  struct bme280_t sensor;
/* USER CODE END PV */

void SystemClock_Config(void);

/* USER CODE BEGIN PFP */
/* Private function prototypes -----------------------------------------------*/
static void LCD_Config(void);
uint8_t* Hex2str(uint32_t*, uint32_t, uint8_t*);

/* USER CODE END PFP */

int main(void)
{

  /* MCU Configuration----------------------------------------------------------*/

  /* Reset of all peripherals, Initializes the Flash interface and the Systick. */
  HAL_Init();

  /* Configure the system clock */
  SystemClock_Config();

  /* Initialize all configured peripherals */
  MX_GPIO_Init();
 // MX_LTDC_Init();
  MX_SPI4_Init();
  MX_SPI5_Init();
  MX_FMC_Init();
  MX_I2C3_Init();
  MX_DMA2D_Init();

  /* USER CODE BEGIN 2 */
  LCD_Config();

  BSP_LCD_SetFont (&LCD_LOG_TEXT_FONT);
  uint8_t array[50]={0};
  uint8_t outbuf[50]={0};

  /* The variable used to assign the standby time*/
  	u8 v_stand_by_time_u8 = BME280_INIT_VALUE;
  	/* The variable used to read uncompensated temperature*/
  	s32 v_data_uncomp_temp_s32 = BME280_INIT_VALUE;
  	/* The variable used to read uncompensated pressure*/
  	s32 v_data_uncomp_pres_s32 = BME280_INIT_VALUE;
  	/* The variable used to read uncompensated pressure*/
  	s32 v_data_uncomp_hum_s32 = BME280_INIT_VALUE;
  	/* The variable used to read compensated temperature*/
  	s32 v_comp_temp_s32[2] = {BME280_INIT_VALUE, BME280_INIT_VALUE};
  	/* The variable used to read compensated pressure*/
  	u32 v_comp_press_u32[2] = {BME280_INIT_VALUE, BME280_INIT_VALUE};
  	/* The variable used to read compensated humidity*/
  	u32 v_comp_humidity_u32[2] = {BME280_INIT_VALUE, BME280_INIT_VALUE};

  BME280_RETURN_FUNCTION_TYPE ret_rslt = ERROR_BME280;

/*
  sensor.bus_write = BME280_I2C_bus_write;
  sensor.bus_read = BME280_I2C_bus_read;
  sensor.dev_addr = BME280_I2C_ADDRESS1;
  sensor.delay_msec = BME280_delay_msek;
*/
  ret_rslt = I2C_routine(&sensor);
  ret_rslt += bme280_init(&sensor);
  /*
  uint32_t id=sensor.chip_id;
  Hex2str((&id), 1, outbuf);
  BSP_LCD_DisplayStringAt(0, 80, outbuf, LEFT_MODE);
  *outbuf='/0';
*/
  ret_rslt += bme280_set_power_mode(BME280_NORMAL_MODE);
  ret_rslt += bme280_set_oversamp_humidity(BME280_OVERSAMP_1X);
  ret_rslt += bme280_set_oversamp_pressure(BME280_OVERSAMP_1X);
  ret_rslt += bme280_set_oversamp_temperature(BME280_OVERSAMP_1X);

  ret_rslt += bme280_set_standby_durn(BME280_STANDBY_TIME_1_MS);
  ret_rslt += bme280_get_standby_durn(&v_stand_by_time_u8);

/*
  HAL_I2C_Mem_Read(&hi2c3, (uint16_t) 0xec, (uint16_t) BME280_HUMIDITY_MSB_REG, I2C_MEMADD_SIZE_8BIT, &array[0], 1, 100) ;
  HAL_I2C_Mem_Read(&hi2c3, (uint16_t) 0xec, (uint16_t) BME280_HUMIDITY_LSB_REG, I2C_MEMADD_SIZE_8BIT, &array[1], 1, 100) ;
 // BME280_I2C_bus_read(0xec,0xd0,array,1);
  Hex2str((uint8_t*)&array[0], 1, outbuf);
   BSP_LCD_DisplayStringAt(0, 0, outbuf, LEFT_MODE);
   Hex2str((uint8_t*)&array[1], 1, outbuf);
    BSP_LCD_DisplayStringAt(0, 20, outbuf, LEFT_MODE);

*/
  if (!ret_rslt) //all ok
	  BSP_LED_On(LED3);
  /* USER CODE END 2 */

  /* Infinite loop */
  while (1)
  {

  /* USER CODE BEGIN 3 */
	  ret_rslt += bme280_read_uncomp_temperature(&v_data_uncomp_temp_s32);
	     ret_rslt += bme280_read_uncomp_pressure(&v_data_uncomp_pres_s32);
	    	ret_rslt += bme280_read_uncomp_humidity(&v_data_uncomp_hum_s32);
	   	ret_rslt += bme280_read_uncomp_pressure_temperature_humidity(
	    	&v_data_uncomp_temp_s32, &v_data_uncomp_pres_s32, &v_data_uncomp_hum_s32);

	   	v_comp_temp_s32[0] = bme280_compensate_temperature_int32(
	   				v_data_uncomp_temp_s32);
	   		v_comp_press_u32[0] = bme280_compensate_pressure_int32(
	   				v_data_uncomp_pres_s32);
	   		v_comp_humidity_u32[0] = bme280_compensate_humidity_int32(
	   				v_data_uncomp_hum_s32);
	   		ret_rslt += bme280_read_pressure_temperature_humidity(
	   		&v_comp_press_u32[1], &v_comp_temp_s32[1],  &v_comp_humidity_u32[1]);

	   	LCD_LOG_ClearTextZone();
	   	/*
	    Hex2str((uint32_t*)&v_comp_temp_s32[1], 1, outbuf);
	    BSP_LCD_DisplayStringAt(0, 0, outbuf, LEFT_MODE);

	    Hex2str((uint32_t*)&v_comp_press_u32[1], 1, outbuf);
	     BSP_LCD_DisplayStringAt(0, 20, outbuf, LEFT_MODE);

	     Hex2str((uint32_t*)&v_comp_humidity_u32[1], 1, outbuf);
	      BSP_LCD_DisplayStringAt(0, 40, outbuf, LEFT_MODE);
*/
	    sprintf(outbuf,"t=%+ld C",v_comp_temp_s32[1]);
        BSP_LCD_DisplayStringAt(0, 0, outbuf, LEFT_MODE);
	    sprintf(outbuf,"p=%-.3ld mm Hg",v_comp_press_u32[1]*75/1000);
        BSP_LCD_DisplayStringAt(0, 20, outbuf, LEFT_MODE);
	    sprintf(outbuf,"h=%ld %%",v_comp_humidity_u32[1]);
        BSP_LCD_DisplayStringAt(0, 40, outbuf, LEFT_MODE);

	      HAL_Delay(1000);
  }
  /* USER CODE END 3 */

}

/** System Clock Configuration
*/
void SystemClock_Config(void)
{

  RCC_OscInitTypeDef RCC_OscInitStruct;
  RCC_ClkInitTypeDef RCC_ClkInitStruct;
  RCC_PeriphCLKInitTypeDef PeriphClkInitStruct;

    /**Configure the main internal regulator output voltage
    */
  __HAL_RCC_PWR_CLK_ENABLE();

  __HAL_PWR_VOLTAGESCALING_CONFIG(PWR_REGULATOR_VOLTAGE_SCALE1);

    /**Initializes the CPU, AHB and APB busses clocks
    */
  RCC_OscInitStruct.OscillatorType = RCC_OSCILLATORTYPE_HSE;
  RCC_OscInitStruct.HSEState = RCC_HSE_ON;
  RCC_OscInitStruct.PLL.PLLState = RCC_PLL_ON;
  RCC_OscInitStruct.PLL.PLLSource = RCC_PLLSOURCE_HSE;
  RCC_OscInitStruct.PLL.PLLM = 4;
  RCC_OscInitStruct.PLL.PLLN = 180;
  RCC_OscInitStruct.PLL.PLLP = RCC_PLLP_DIV2;
  RCC_OscInitStruct.PLL.PLLQ = 7;
  if (HAL_RCC_OscConfig(&RCC_OscInitStruct) != HAL_OK)
  {
    _Error_Handler(__FILE__, __LINE__);
  }

    /**Activate the Over-Drive mode
    */
  if (HAL_PWREx_EnableOverDrive() != HAL_OK)
  {
    _Error_Handler(__FILE__, __LINE__);
  }

    /**Initializes the CPU, AHB and APB busses clocks
    */
  RCC_ClkInitStruct.ClockType = RCC_CLOCKTYPE_HCLK|RCC_CLOCKTYPE_SYSCLK
                              |RCC_CLOCKTYPE_PCLK1|RCC_CLOCKTYPE_PCLK2;
  RCC_ClkInitStruct.SYSCLKSource = RCC_SYSCLKSOURCE_PLLCLK;
  RCC_ClkInitStruct.AHBCLKDivider = RCC_SYSCLK_DIV1;
  RCC_ClkInitStruct.APB1CLKDivider = RCC_HCLK_DIV4;
  RCC_ClkInitStruct.APB2CLKDivider = RCC_HCLK_DIV2;

  if (HAL_RCC_ClockConfig(&RCC_ClkInitStruct, FLASH_LATENCY_5) != HAL_OK)
  {
    _Error_Handler(__FILE__, __LINE__);
  }

  PeriphClkInitStruct.PeriphClockSelection = RCC_PERIPHCLK_LTDC;
  PeriphClkInitStruct.PLLSAI.PLLSAIN = 60;
  PeriphClkInitStruct.PLLSAI.PLLSAIR = 5;
  PeriphClkInitStruct.PLLSAIDivR = RCC_PLLSAIDIVR_4;
  if (HAL_RCCEx_PeriphCLKConfig(&PeriphClkInitStruct) != HAL_OK)
  {
    _Error_Handler(__FILE__, __LINE__);
  }

    /**Configure the Systick interrupt time
    */
  HAL_SYSTICK_Config(HAL_RCC_GetHCLKFreq()/1000);

    /**Configure the Systick
    */
  HAL_SYSTICK_CLKSourceConfig(SYSTICK_CLKSOURCE_HCLK);

  /* SysTick_IRQn interrupt configuration */
  HAL_NVIC_SetPriority(SysTick_IRQn, 0, 0);
}

/* USER CODE BEGIN 4 */
static void LCD_Config(void)
{
  /* LCD Initialization */
  BSP_LCD_Init();

  /* LCD Layers Initialization */
  BSP_LCD_LayerDefaultInit(LCD_FOREGROUND_LAYER, (LCD_FRAME_BUFFER + BUFFER_OFFSET));

  /* Configure the transparency for foreground : Increase the transparency */
  BSP_LCD_SetTransparency(LCD_BACKGROUND_LAYER, 0);
  BSP_LCD_SelectLayer(LCD_FOREGROUND_LAYER);

  /* LCD Log initialization */

  LCD_LOG_Init();

 // LCD_LOG_SetHeader((uint8_t *)"meteo Application");

  LCD_LOG_SetFooter ((uint8_t *)"     Meteo Application" );

}

//____________________________________________________________________________/
uint8_t* Hex2str(uint32_t* inarr, uint32_t size, uint8_t* out)
{
	uint8_t symbol_count = 2*sizeof(*inarr);

	for(uint32_t i=0; i < size; i++)
	{
		for(int8_t j = symbol_count-1, k = 0; j >= 0 ; j--, k++)
		{
			uint32_t temp = 0;
			temp = *(inarr+i) >> (4*j);
			temp &= 0xf;
			if(temp < 0xa)
			{
				*(out+i*symbol_count+k)= '0' + temp; 	  //numbers
			}
			else
			{
				*(out+i*symbol_count+k)= 'a' + (temp - 0xa); //letters
			}

		}
	}
	out[size*symbol_count]='\0';
	return out;
}

/* USER CODE END 4 */

void _Error_Handler(char * file, int line)
{
  /* USER CODE BEGIN Error_Handler_Debug */
  /* User can add his own implementation to report the HAL error return state */
	BSP_LED_On(LED3);
	BSP_LED_On(LED4);
  while(1)
  {
  }
  /* USER CODE END Error_Handler_Debug */
}

/************************ (C) COPYRIGHT STMicroelectronics *****END OF FILE****/
